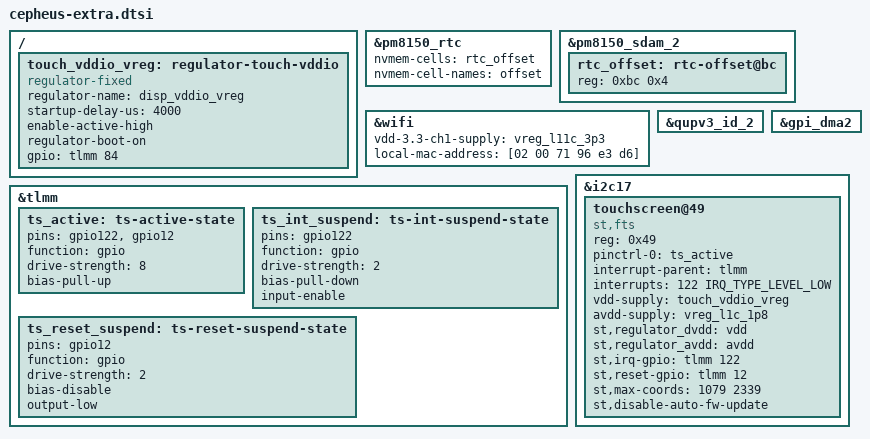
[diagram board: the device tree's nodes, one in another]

/*
 * ============================================================================
 *  Xiaomi Mi 9 (cepheus, SM8150) —— 板级启用补丁 第 2 部分
 *  追加到 arch/arm64/boot/dts/qcom/sm8150-xiaomi-cepheus.dts 末尾
 *  （第 1 部分 cepheus-wifi.dtsi 必须已经打上）
 *  ----------------------------------------------------------------------------
 *  本文件只解决四件事，逐条都来自实测日志（docs/root-cause.md §10.12/§10.13）：
 *
 *    1) RTC   ：时间写不进去（hwclock -w → Invalid argument）
 *               根因：rtc-pm8xxx 的 set_time 既没有 allow-set-time，
 *               也没有 nvmem offset cell → 走 pm8xxx_rtc_update_offset()
 *               却拿不到 cell → -ENODEV。
 *               做法照抄同门机型 nabu/raphael：用 SDAM 的 nvmem cell 存偏差。
 *    2) WiFi  ：warn `supply vdd-3.3-ch1 not found` + `invalid MAC address`
 *    3) 触摸  ：STM FTS，挂 i2c17（SE17 = gpio55/56）
 *
 *  ⚠️ 几条**故意不写**的东西（都是查证后否掉的，别再"顺手补上"）：
 *
 *    * &usb_1_qmpphy 的两路电：上游 sm8150-xiaomi-cepheus.dts 里**已经有了**
 *      （vdda-phy = vreg_l3c_1p2 / vdda-pll = vreg_l5a_0p875）。
 *      usb12 那条 err `qcom-qmp-combo-phy 88e8000.phy: failed at
 *      devm_regulator_bulk_get` 不是缺电，是**早期 -EPROBE_DEFER 被 dev_err
 *      打了出来**：实测开机后 88e8000.phy 已绑定 qcom-qmp-combo-phy、
 *      /sys/class/phy/ 下有两个 phy。改 DTB 反而会把真实电源轨改错。
 *      → 用仓库补丁 0003（换 dev_err_probe）解决，不动 DT。
 *
 *    * ITS 节点（arm,gic-v3-its）：厂商 DT 里根本没有 ITS，也查不到
 *      SM8150 的 ITS 地址证据。乱加一个地址错了会引入**新的**报错。
 *      `ITS: No ITS available, not enabling LPIs` 是信息性的，先留着。
 *
 *    * display-subsystem / dpu / dsi：**千万别在这里开**。本机现在能看屏幕，
 *      靠的是 edk2 GOP + 内核 efifb（/dev/fb0 已存在）。把 DRM(msm) 的 mdss
 *      打开而面板驱动又不存在，efifb 会被顶掉，屏幕反而黑。
 *      真显示栈（DPU+DSI+面板）留到后面单独做。
 * ============================================================================
 */


/* ==========================================================================
 * 1) RTC：把「写时间」这条路打通
 *
 *    rtc-pm8xxx.c 的 set_time 只有两种走法：
 *        if (rtc_dd->allow_set_time)
 *                __pm8xxx_rtc_set_time()      ← 直接写 RTC 寄存器
 *        else
 *                pm8xxx_rtc_update_offset()   ← 把 (目标时间 - RTC时间) 存进
 *                                               nvmem cell，读的时候再加回来
 *    两条都没配 → offset 那条拿不到 cell → -ENODEV。
 *
 *    ★ 选 offset 而不是 allow-set-time 的理由：
 *      sm8150-xiaomi-nabu.dts / sm8150-xiaomi-raphael.dts（同 SM8150、同 PMIC、
 *      同一套小米 ABL）用的就是这个写法，是可复现的先例；而且它**不需要写
 *      RTC 寄存器**，不受"RTC 可能被 modem/ABL 占着"的影响。
 *      （要换成直写，就把 nvmem-cells 两行换成 `allow-set-time;`。）
 *
 *    配套：payload 里有 rtc-save.service/timer，定期用 busybox hwclock -w
 *    把系统时间落盘到这里 —— 内核自带的 RTC_SYSTOHC 需要 userspace 通过
 *    adjtimex 上报"已同步"，systemd-timesyncd 不报，所以那套机制在本机永不触发。
 * ========================================================================== */
&pm8150_rtc {
	status = "okay";

	nvmem-cells = <&rtc_offset>;
	nvmem-cell-names = "offset";
};

&pm8150_sdam_2 {
	status = "okay";

	/* 0xbc/4 这两个数字取自 nabu/raphael，同一个 PMIC 同一个用途 */
	rtc_offset: rtc-offset@bc {
		reg = <0xbc 0x4>;
	};
};


/* ==========================================================================
 * 2) WiFi 收尾
 * ========================================================================== */
&wifi {
	/*
	 * 第 5 路电。ath10k_snoc 的 ath10k_regulators[] 里一共 5 个名字
	 * （含 "vdd-3.3-ch1"），DT 里没写的会 fallback 成 dummy regulator，
	 * 于是每次开机一条 warn。
	 * 厂商 icnss 节点里**只有** vdd-3.3-ch0（ch1 在 cepheus 上做进了同一路
	 * 3.3V），所以这里直接复用 ch0 的那路 PM8150L LDO11。
	 */
	vdd-3.3-ch1-supply = <&vreg_l11c_3p3>;

	/*
	 * 固定 MAC：本地管理位（第二个字节 bit1）置 1 的 02:00:...
	 * 与 payload 里 NetworkManager 档案的
	 * cloned-mac-address=02:00:71:96:e3:d6 完全一致 ——
	 * 内核态与用户态看到的是同一个地址，不会再"每次开机随机"。
	 *
	 * 注意：上游 ath10k 不读 DT 的 MAC，只认固件给的（固件给的是全 0/无效
	 * → 才有那条 "invalid MAC address; choosing random"）。
	 * 真正生效靠仓库补丁 0002-ath10k-use-dt-mac-address.patch。
	 */
	local-mac-address = [02 00 71 96 e3 d6];
};


/* ==========================================================================
 * 3) 触摸：STM FTS（FingerTipS / FTM5）
 * --------------------------------------------------------------------------
 *  硬件（全部抄自厂商 DT 的 fts@49 节点）：
 *      I2C   ：i2c17（SE17，gpio55/56，函数 qup17）
 *      IRQ   ：TLMM gpio122，低电平有效
 *      RESET ：TLMM gpio12，高有效
 *      avdd  ：PM8150L LDO1（1.8V）
 *      vdd   ：厂商 DT 里叫 touch_vddio_vreg —— 由 TLMM gpio84 使能的
 *              fixed regulator（regulator-name 是 disp_vddio_vreg）
 *
 *  驱动（这棵树里的版本 drivers/input/touchscreen/fts_touch/）：
 *      * 只认 **st,** 前缀的属性。厂商 DTB 里那套 fts,* 是给小米原厂
 *        驱动用的，这个驱动一个都不读 —— 照抄厂商节点必然 probe 失败。
 *      * 中断不是从 DT 的 interrupts 属性拿的，而是
 *            info->client->irq = gpio_to_irq(info->board->irq_gpio);
 *        所以 st,irq-gpio 才是关键（interrupts 只是让 i2c 核心也认一下）。
 *      * 它不用 pinctrl（只 include 了 consumer.h，没有 pinctrl_get），
 *        所以把厂商的"有效态"直接写成 "default"，由驱动核心自动应用。
 *      * 尺寸：默认值是 1440x2560-1，必须用 st,max-coords 覆盖成 1080x2340-1。
 *      * 固件：request_firmware("st_fts_f1.ftb")，但整机（vendor/system/
 *        persist）里都没有这个文件；IC 里烧的是原厂固件、CRC 正常，
 *        开着自动升级只会刷 request_firmware 失败 → 用
 *        st,disable-auto-fw-update 关掉。
 * ========================================================================== */

/* 3a) 触摸 I/O 供电（厂商 DT 的 touch_vddio_vreg：fixed + TLMM gpio84） */
/ {
	touch_vddio_vreg: regulator-touch-vddio {
		compatible = "regulator-fixed";
		regulator-name = "disp_vddio_vreg";
		startup-delay-us = <4000>;
		enable-active-high;
		regulator-boot-on;
		gpio = <&tlmm 84 GPIO_ACTIVE_HIGH>;
	};
};

/* 3b) pin 配置：数值逐条抄厂商 DT 的 ts_active / ts_int_suspend /
 *     ts_reset_suspend（drive-strength、bias 完全一致）。
 *     "default" 由驱动核心自动应用；后两个现在没人 select，
 *     留着给以后做休眠/灭屏用。 */
&tlmm {
	ts_active: ts-active-state {
		pins = "gpio122", "gpio12";
		function = "gpio";
		drive-strength = <8>;
		bias-pull-up;
	};

	ts_int_suspend: ts-int-suspend-state {
		pins = "gpio122";
		function = "gpio";
		drive-strength = <2>;
		bias-pull-down;
		input-enable;
	};

	ts_reset_suspend: ts-reset-suspend-state {
		pins = "gpio12";
		function = "gpio";
		drive-strength = <2>;
		bias-disable;
		output-low;
	};
};

/* 3c) i2c17 所在的 QUP wrapper（SE17）。
 *     i2c@c80000 与 spi@c80000 共用同一个 SE，只能开一个（我们用 i2c）。 */
&qupv3_id_2 {
	status = "okay";
};

/* 3c-2) SE17 专用的 GPI DMA 控制器（gpi_dma2 @0xc00000）。
 *
 *   第一版漏了这条，实测症状（新 DTB 首启 dmesg）：
 *       platform c80000.i2c: deferred probe pending:
 *                geni_i2c: Failed to get tx DMA ch
 *   → i2c 控制器一直在 deferred probe，/sys/bus/i2c/devices 全空，
 *     触摸自然永远不 probe。（i2c-qcom-geni 驱动里 dma_request_chan()
 *     返回 -EPROBE_DEFER 就是整个 probe 失败，不会退化成 FIFO。）
 *
 *   为什么不能指望 FIFO 兜底：驱动 probe 时会读硬件寄存器
 *   GENI_IF_DISABLE_RO 的 FIFO_IF_DISABLE 位，SM8150 的 SE 上这一位是 1
 *   （FIFO 接口被禁用）→ 只允许 GENI_GPI_DMA 模式，必须把 DMA 控制器开起来。
 *
 *   sm8150.dtsi 里三个 gpi_dma 默认全是 disabled，官方 board dts 谁用谁开。 */
&gpi_dma2 {
	status = "okay";
};

/* 3d) 触摸本体 */
&i2c17 {
	status = "okay";

	touchscreen@49 {
		compatible = "st,fts";
		reg = <0x49>;

		pinctrl-names = "default";
		pinctrl-0 = <&ts_active>;

		interrupt-parent = <&tlmm>;
		interrupts = <122 IRQ_TYPE_LEVEL_LOW>;

		vdd-supply = <&touch_vddio_vreg>;
		avdd-supply = <&vreg_l1c_1p8>;
		/* 驱动用这两个字符串去 devm_regulator_get()：
		 * "vdd"/"avdd" 正好对应上面两条 *-supply */
		st,regulator_dvdd = "vdd";
		st,regulator_avdd = "avdd";

		st,irq-gpio = <&tlmm 122 IRQ_TYPE_LEVEL_LOW>;
		st,reset-gpio = <&tlmm 12 GPIO_ACTIVE_HIGH>;

		/* 1080x2340 → 取 N-1（驱动默认 1440x2560-1，不写就错） */
		st,max-coords = <1079 2339>;

		/* 见文件头说明：没有 .ftb 固件，关掉自动升级 */
		st,disable-auto-fw-update;
	};
};
